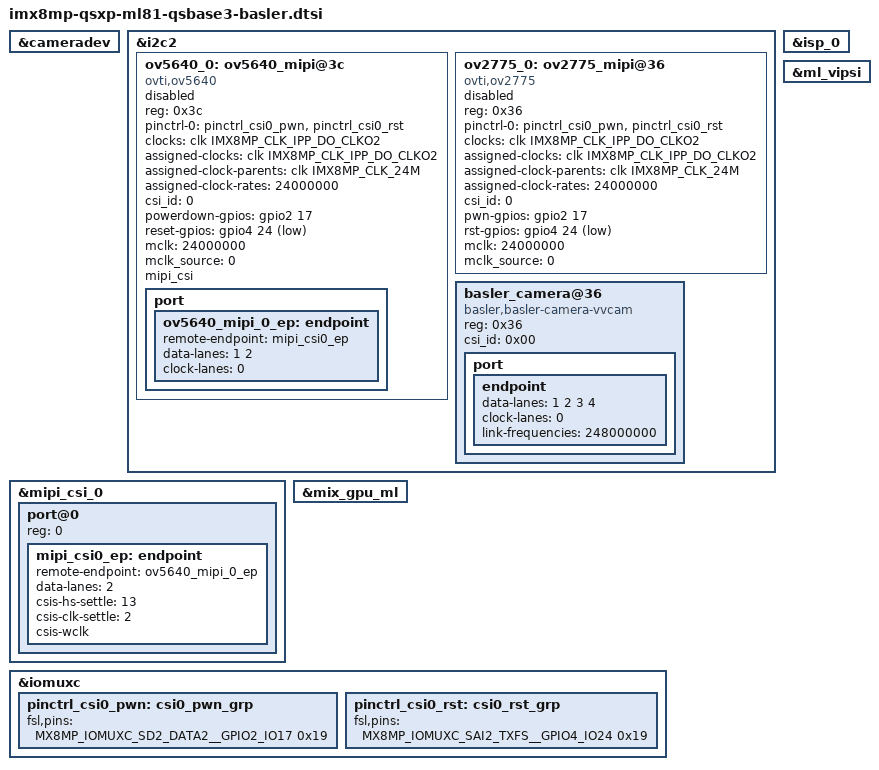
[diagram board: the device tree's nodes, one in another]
// SPDX-License-Identifier: (GPL-2.0 OR MIT)
/*
 * Copyright (C) 2020 Markus Bauer <mb@karo-electronics.de>
 *
 */

&cameradev {
	status = "okay";
};

&i2c2 {
	ov5640_0: ov5640_mipi@3c {
		compatible = "ovti,ov5640";
		reg = <0x3c>;
		pinctrl-names = "default";
		pinctrl-0 = <&pinctrl_csi0_pwn>, <&pinctrl_csi0_rst>;
		clocks = <&clk IMX8MP_CLK_IPP_DO_CLKO2>;
		clock-names = "xclk";
		assigned-clocks = <&clk IMX8MP_CLK_IPP_DO_CLKO2>;
		assigned-clock-parents = <&clk IMX8MP_CLK_24M>;
		assigned-clock-rates = <24000000>;
		csi_id = <0>;
		powerdown-gpios = <&gpio2 17 GPIO_ACTIVE_HIGH>;
		reset-gpios = <&gpio4 24 GPIO_ACTIVE_LOW>;
		mclk = <24000000>;
		mclk_source = <0>;
		mipi_csi;
		status = "disabled";

		port {
			ov5640_mipi_0_ep: endpoint {
				remote-endpoint = <&mipi_csi0_ep>;
				data-lanes = <1 2>;
				clock-lanes = <0>;
			};
		};
	};

	ov2775_0: ov2775_mipi@36 {
		compatible = "ovti,ov2775";
		reg = <0x36>;
		pinctrl-names = "default";
		pinctrl-0 = <&pinctrl_csi0_pwn>, <&pinctrl_csi0_rst>;
		clocks = <&clk IMX8MP_CLK_IPP_DO_CLKO2>;
		clock-names = "csi_mclk";
		assigned-clocks = <&clk IMX8MP_CLK_IPP_DO_CLKO2>;
		assigned-clock-parents = <&clk IMX8MP_CLK_24M>;
		assigned-clock-rates = <24000000>;
		csi_id = <0>;
		pwn-gpios = <&gpio2 17 GPIO_ACTIVE_HIGH>;
		rst-gpios = <&gpio4 24 GPIO_ACTIVE_LOW>;
		mclk = <24000000>;
		mclk_source = <0>;
		status = "disabled";
	};

	basler_camera@36 {
		compatible = "basler,basler-camera-vvcam", "basler-camera-vvcam";
		reg = <0x36>;
		csi_id = <0x00>;
		status = "okay";

		port {
			endpoint {
				data-lanes = <1 2 3 4>;
				clock-lanes = <0>;
				link-frequencies = /bits/ 64 <248000000>;
			};
		};
	};
};

&isp_0 {
	status = "okay";
};

&mipi_csi_0 {
	status = "okay";

	port@0 {
		reg = <0>;
		mipi_csi0_ep: endpoint {
			remote-endpoint = <&ov5640_mipi_0_ep>;
			data-lanes = <2>;
			csis-hs-settle = <13>;
			csis-clk-settle = <2>;
			csis-wclk;
		};
	};
};

&ml_vipsi {
	status = "okay";
};

&mix_gpu_ml {
	status = "okay";
};

&iomuxc {
	pinctrl_csi0_pwn: csi0_pwn_grp {
		fsl,pins = <
			MX8MP_IOMUXC_SD2_DATA2__GPIO2_IO17		0x19
		>;
	};

	pinctrl_csi0_rst: csi0_rst_grp {
		fsl,pins = <
			MX8MP_IOMUXC_SAI2_TXFS__GPIO4_IO24		0x19
		>;
	};
};
